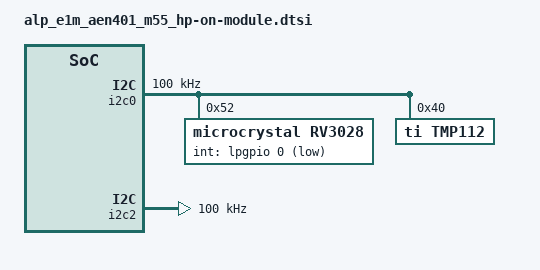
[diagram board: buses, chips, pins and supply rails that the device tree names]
/*
 * Copyright (c) 2026 Alp Lab AB
 * SPDX-License-Identifier: Apache-2.0
 *
 * E1M-AEN401 on-module devices: the BRD_I2C bus (RV-3028, TMP112), the E1M
 * I2C0 bus (SoC I2C2, alp-i2c0) and the alp,som-power node.  The AEN401 board
 * tree is hand-written (the generator cannot emit an E4 board yet,
 * tests/scripts/test_gen_zephyr_board.py NOT_EMITTABLE), but these blocks are
 * the generator's own output for this SKU: scripts/gen_zephyr_board.py
 * _aen_brd_i2c_dts(links, "E4"), _aen_e1m_i2c0_dts(links) and
 * _aen_som_power_dts(E1M-AEN401 preset, ...).  DO NOT EDIT BY HAND --
 * test_gen_zephyr_board.py fails when this file and the generator disagree.
 */

#include <zephyr/dt-bindings/gpio/gpio.h>

/*
 * BRD_I2C -- the on-module housekeeping bus: SoC I2C0 in its function-C
 * muxing (P7_0 SDA / P7_1 SCL), NOT the slave-only LPI2C0 it was
 * believed to be before #1848.  Driven by UPSTREAM
 * Zephyr i2c_dw ("snps,designware-i2c"), ADR 0017 Tier-1 -- no vendored code.
 *
 * ISOLATED: R93/R94 (the 0-ohm bridge to the I2C2/EEPROM segment) are DNP, so
 * the 24C128 manifest EEPROM is NOT on this bus -- it stays on i2c2.  The
 * OPTIGA Trust M (IC1, @0x30) is DNP=1 on this batch and so has NO node here;
 * its silence is a negative control, not a fault.
 *
 * Both device drivers are upstream and Kconfig `default y` on their own
 * DT_HAS_*_ENABLED, so an app needs only CONFIG_RTC / CONFIG_SENSOR in its
 * prj.conf -- the board layer deliberately forces neither.
 */
&i2c0 {
	status = "okay";
	pinctrl-0 = <&pinctrl_i2c0>;
	pinctrl-names = "default";
	clock-frequency = <I2C_BITRATE_STANDARD>;

	/*
	 * E1M-AEN-2626-R2 components CSV: U21 = RV-3028-C7, DNP=0 fitted. Bench
	 * 2026-09-05: ACKs at 0x52, ID register 0x28 reads 0x44, and the seconds
	 * register advanced 0x01 -> 0x02, so the oscillator is RUNNING. CAVEAT for
	 * docs and examples: with no VBACKUP cell the RTC does NOT retain time or a
	 * pending alarm across a power cycle on this batch.
	 */
	rv3028: rtc@52 {
		compatible = "microcrystal,rv3028";
		reg = <0x52>;
		backup-switch-mode = "disabled";
		int-gpios = <&lpgpio 0 GPIO_ACTIVE_LOW>;
	};

	/*
	 * E1M-AEN-2626-R2 components CSV: U20 = TMP112DIDPWR, DNP=0 fitted, ADD0 tied
	 * to 0V. Per TI SBOS473L p.44 (package option addendum), the exact orderable
	 * MPN TMP112DIDPWR is X2SON (DPW), 5 pins -- no SOT563-6 orderable carries
	 * that MPN (the SOT563-6 parts are TMP112AIDRLR / TMP112BIDRLR /
	 * TMP112NAIDRLR). Per TI SBOS473L Table 7-4, the X2SON-5 "Address Variant
	 * Only" TMP112D row straps ADD0->GND = 0x40 (->V+ = 0x41, ->SDA = 0x42, ->SCL
	 * = 0x43); the SOT563-6 "Address + Alert Variant" row (ADD0->GND = 0x48) does
	 * not apply to this MPN. So 0x40 is the DESIGN address for the part this
	 * board specifies, and the bench observation matches that design rather than
	 * being an anomaly to explain away: two bench units answered at 0x40 instead
	 * of 0x48 (28.062 degC, 2026-09-05; 27.687 degC, 2026-09-07, serial
	 * 2026W36-0002), each confirming a three-of-three TMP112 register fingerprint
	 * (CONFIG=0x60a0, T_LOW=0x4b00, T_HIGH=0x5000, the datasheet power-on
	 * defaults). Design and silicon agree, so this entry and the devicetree node
	 * it emits now both carry 0x40; the earlier 0x48 was simply wrong, which is
	 * also why the stock CONFIG_TMP112 driver never bound -- the node put it at
	 * an address nothing answers. Recorded under alp-sdk#1978.
	 */
	tmp112: tmp112@40 {
		compatible = "ti,tmp112";
		reg = <0x40>;
	};
};

/*
 * lpgpio -- needed so the RV-3028 alarm on P15_0 (RTC_ALARM, bit 0 =>
 * IRQ 171) is usable as an interrupt source.  Active LOW,
 * open-drain, pulled up on-module by R98 (100k to +1V8, FITTED).  The pad
 * itself is muxed in the pinctrl dtsi's BRD_I2C group (that binding has no
 * pinctrl-0 of its own).
 */
&lpgpio {
	status = "okay";
};

/*
 * Portable aliases.  The bus alias is what alp_i2c_open(.bus_id = N)
 * resolves (src/backends/i2c/zephyr_drv.c -> DT_ALIAS(alp_i2cN)), matching
 * the on-module EEPROM's own convention on i2c2; the device aliases let an
 * example say DT_ALIAS(rtc) / DT_ALIAS(alp_temp0) instead of hardcoding
 * this board's node labels.
 */
/ {
	aliases {
		alp-i2c2 = &i2c0;
		rtc = &rv3028;
		alp-temp0 = &tmp112;
	};
};

/*
 * e1m_i2c0 -- SoC I2C2 in its function-C muxing (P5_7 SDA / P5_6 SCL), portable
 * alp-i2c0 (E1M edge bus 0).  Carries the SoM's own 24C128 manifest
 * EEPROM; the same physical bus also reaches the EVK carrier's sensor bus
 * once the pads leave the module (docs/bring-up-aen.md Sec 5.1).  Driven by
 * UPSTREAM Zephyr i2c_dw ("snps,designware-i2c"), ADR 0017 Tier-1 -- no
 * vendored code.
 */
&i2c2 {
	status = "okay";
	pinctrl-0 = <&pinctrl_i2c2>;
	pinctrl-names = "default";
	clock-frequency = <I2C_BITRATE_STANDARD>;
};

/*
 * Portable alias for e1m_i2c0.  alp_i2c_open(.bus_id = ALP_E1M_I2C0)
 * resolves this via src/backends/i2c/zephyr_drv.c -> DT_ALIAS(alp_i2c0);
 * matches the EEPROM manifest reader's own
 * CONFIG_ALP_SDK_HW_INFO_EEPROM_I2C_BUS_ID=0 convention.
 */
/ {
	aliases {
		alp-i2c0 = &i2c2;
	};
};

/*
 * SoM power domains (alp-sdk#2784): which on-module chips this SKU carries,
 * the SoC pads that gate them, and the default quiesce action per domain.
 * Presence follows this SKU's `on_module` block; pads, polarity and actions
 * come from `power_domains:` in metadata/e1m_modules/aen/on-module-links.yaml.
 * The SoM power layer (src/backends/power/som_power.c) reads this node and
 * applies its pinctrl-0 state before it first drives a pad.  `alp,stop-hold` is
 * "unproven" for every LPGPIO (P15_n) pad until the STOP bench shows the output
 * holds.
 */
&pinctrl {
	pinctrl_som_power: pinctrl_som_power {
		group0 {
			pinmux = <PIN_P5_5__GPIO>, <PIN_P11_6__GPIO>, <PIN_P15_1__LPGPIO>, <PIN_P15_4__LPGPIO>, <PIN_P15_5__LPGPIO>, <PIN_P15_6__LPGPIO>, <PIN_P15_7__LPGPIO>;
			input-enable;
			input-schmitt-enable;
		};
	};
};

/ {
	som_power: som-power {
		compatible = "alp,som-power";
		pinctrl-0 = <&pinctrl_som_power>;
		pinctrl-names = "default";
		/* SoM-wired LPGPIO pads without a domain node (alif-ospi.tsv):
		 * OSPI1_INTn P15_2, OSPI0_INTn P15_3, OSPI0_RESETn P15_6, OSPI1_RESETn P15_7.
		 * Never an application wake pad. */
		alp,wired-lpgpio-pads = <2 3 6 7>;

		/*
		 * E_WIFI_NRST / WIFI_EN pads: inter-chip.tsv rows E_WIFI_NRST (P15_1_FLEX)
		 * and WIFI_EN (P15_5); roles per docs/cc3501e-bridge.md ("WIFI_EN gates
		 * VPA", "E_WIFI.NRST: Alif resets the CC3501E"). Savings: bench 2026-10-08,
		 * E1M-AEN803 on an E1M-EVK (board-input PSU telemetry at 16.0 V, 1 mA
		 * resolution, RAM-run). E_WIFI_NRST is active-low, bench-verified the same
		 * run: held LOW the CC3501E PING returns -5, released it returns 0. Restore
		 * semantics: chips/cc3501e/cc3501e_core.c cc3501e_reset() vs
		 * cc3501e_hard_reset().
		 */
		som_pd_wifi_ble: wifi-ble {
			compatible = "alp,som-power-domain";
			alp,role = "wifi_ble";
			reset-gpios = <&lpgpio 1 GPIO_ACTIVE_LOW>; /* E_WIFI_NRST P15_1 */
			enable-gpios = <&lpgpio 5 GPIO_ACTIVE_HIGH>; /* WIFI_EN P15_5 */
			alp,chip = "cc3501e";
			alp,default-action = "hold_reset";
			alp,default-modes = "stop", "standby";
			alp,stop-hold = "unproven";
			alp,restore = "nreset_release";
			alp,rail-off-opt-in;
			alp,dependents = "cam_ldo";
		};

		/*
		 * alif-ethernet-phy.tsv rows E_PHY_RESET (P11_6) and E_PHY_PWRDWN (P15_4);
		 * docs/aen-bench-bringup.md ("PHY power E_PHY_PWRDWN = P15_4 lpgpio, PHY
		 * reset E_PHY_RESET = P11_6 gpio11"). Polarity bench-verified 2026-10-08
		 * (E1M-AEN803 on an E1M-EVK, RAM-run, MDIO): E_PHY_PWRDWN HIGH powers the
		 * PHY (ID 2000a140 reads), LOW turns it off (ID gone, stale reads);
		 * E_PHY_RESET held LOW reads every MDIO register as 0xffff, release brings
		 * the ID back. Savings: bench 2026-10-08, RAM-run, all three methods.
		 */
		som_pd_eth_phy: eth-phy {
			compatible = "alp,som-power-domain";
			alp,role = "eth_phy";
			powerdown-gpios = <&lpgpio 4 GPIO_ACTIVE_LOW>; /* E_PHY_PWRDWN P15_4 */
			reset-gpios = <&gpio11 6 GPIO_ACTIVE_LOW>; /* E_PHY_RESET P11_6 */
			alp,chip = "dp83825";
			alp,default-action = "powerdown_pin";
			alp,default-modes = "stop", "standby";
			alp,stop-hold = "unproven";
			alp,restore = "pin_release";
			alp,dependents = "phy_refclk";
		};

		/*
		 * alif-ospi.tsv row OSPI1_RESETn (P15_7); net-to-part mapping per
		 * E1M-AEN-2626-R2 (U10 NOR) as recorded in CHANGELOG.md (the
		 * OSPI1_INTn/OSPI1_RESETn entry).
		 */
		som_pd_ext_flash: ext-flash {
			compatible = "alp,som-power-domain";
			alp,role = "ext_flash";
			reset-gpios = <&lpgpio 7 GPIO_ACTIVE_LOW>; /* OSPI1_RESETn P15_7 */
			alp,chip = "MX25UM25645GXDI00";
			alp,default-action = "hold_reset";
			alp,default-modes = "stop", "standby";
			alp,stop-hold = "unproven";
			alp,restore = "driver_release";
			alp,bom-optional;
		};

		/*
		 * alif-ospi.tsv row OSPI0_RESETn (P15_6); U9 -> OSPI0_SS0 per the
		 * E1M-AEN-2626-R2 netlist (metadata/e1m_modules/E1M-AEN803.yaml
		 * `ospi_memories` comment).
		 */
		som_pd_ext_ram: ext-ram {
			compatible = "alp,som-power-domain";
			alp,role = "ext_ram";
			reset-gpios = <&lpgpio 6 GPIO_ACTIVE_LOW>; /* OSPI0_RESETn P15_6 */
			alp,chip = "W958D8NBYA5I";
			alp,default-action = "hold_reset";
			alp,default-modes = "stop", "standby";
			alp,stop-hold = "unproven";
			alp,restore = "pin_release";
			alp,bom-optional;
		};

		/*
		 * Part and bus per on_module_links.brd_i2c.devices (U20 TMP112DIDPWR).
		 */
		som_pd_temp_sensor: temp-sensor {
			compatible = "alp,som-power-domain";
			alp,role = "temp_sensor";
			alp,device = <&tmp112>;
			alp,chip = "tmp112";
			alp,default-action = "shutdown_reg";
			alp,default-modes = "stop", "standby";
			alp,stop-hold = "none";
			alp,restore = "register_write";
		};

		/*
		 * Part per on_module_links.brd_i2c.devices (U21); /INT -> P15_0 per
		 * on_module_links.rtc_alarm and the inter-chip.tsv RTC_ALARM row. VBACKUP
		 * unpopulated: see the rv3028 device evidence.
		 */
		som_pd_rtc: rtc {
			compatible = "alp,som-power-domain";
			alp,role = "rtc";
			wake-gpios = <&lpgpio 0 GPIO_ACTIVE_LOW>; /* RTC_ALARM P15_0 */
			alp,primary-rtc;
			alp,device = <&rv3028>;
			alp,chip = "rv3028c7";
			alp,default-action = "keep_alive";
			alp,default-modes = "stop", "standby";
			alp,stop-hold = "none";
			alp,restore = "none";
		};

		/*
		 * on_module_links.backlight.enable (P5_5, E1M-AEN-2626-R2 netlist).
		 * `BACKLIGHT_EN` is this file's label, not a netlist name; the asserted
		 * polarity is `assumed`.
		 */
		som_pd_backlight: backlight {
			compatible = "alp,som-power-domain";
			alp,role = "backlight";
			enable-gpios = <&gpio5 5 GPIO_ACTIVE_HIGH>; /* BACKLIGHT_EN P5_5 */
			alp,default-action = "enable_low";
			alp,default-modes = "stop", "standby";
			alp,stop-hold = "no";
			alp,restore = "pin_release";
		};
	};
};

/*
 * GPIO ports carrying a SoM power-domain pad (the SoC peripherals dtsi leaves
 * them disabled).  Without them the SoM power layer cannot drive those pads.
 */
&gpio5 {
	status = "okay";
};

&gpio11 {
	status = "okay";
};
